# ing916 register map
Vendor: INGChips; Series: ing916xx; File version: 522
CPU: CM4 r0p1, little endian, MPU, FPU, VTOR, 5 interrupt priority bits
Registers are 32-bit, read-write, reset 0x0 unless marked. A register's access mark holds for its fields unless they carry their own. Offsets are from the block's base; [hi:lo] are bit positions; {n}, {i} and the like mark numbered series.

## aon2_ctrl
Base 0x40100000
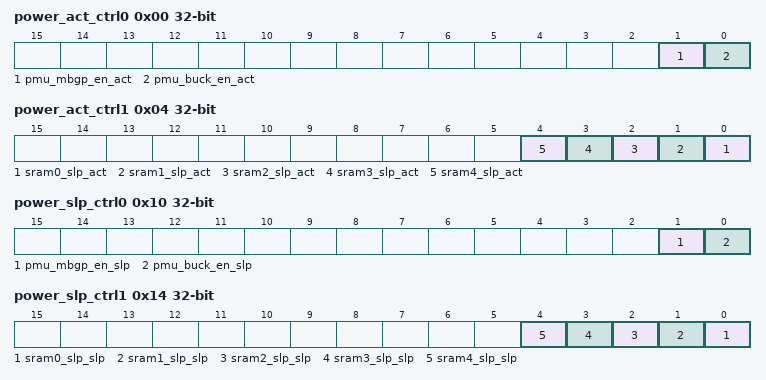
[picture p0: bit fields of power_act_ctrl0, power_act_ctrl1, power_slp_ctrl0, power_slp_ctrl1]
0x00 power_act_ctrl0 — reg description:
  [1] pmu_mbgp_en_act — reg description:
  [0] pmu_buck_en_act — reg description:
0x04 power_act_ctrl1 — reg description:
  [n] sram{n}_slp_act (n=0..4) — reg description:
0x10 power_slp_ctrl0 — reg description:
  [1] pmu_mbgp_en_slp — reg description:
  [0] pmu_buck_en_slp — reg description:
0x14 power_slp_ctrl1 — reg description:
  [n] sram{n}_slp_slp (n=0..4) — reg description:
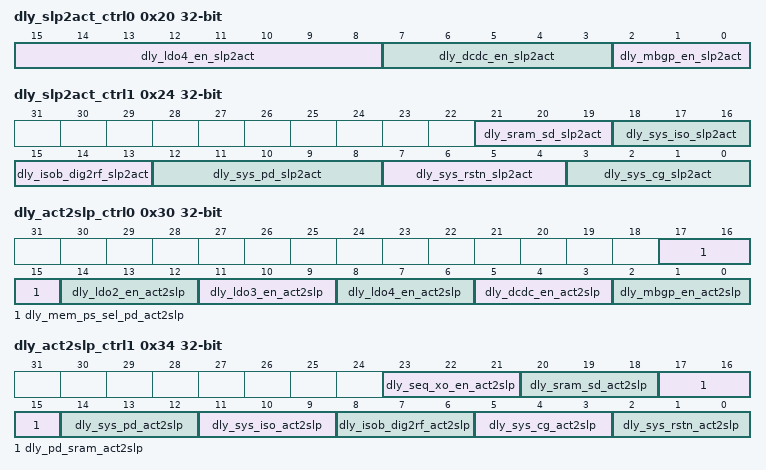
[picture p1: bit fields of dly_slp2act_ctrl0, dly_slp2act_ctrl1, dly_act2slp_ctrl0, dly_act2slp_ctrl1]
0x20 dly_slp2act_ctrl0 — reg description:
  [15:8] dly_ldo4_en_slp2act — reg description:
  [7:3] dly_dcdc_en_slp2act — reg description:
  [2:0] dly_mbgp_en_slp2act — reg description:
0x24 dly_slp2act_ctrl1 — reg description:
  [21:19] dly_sram_sd_slp2act — reg description:
  [18:16] dly_sys_iso_slp2act — reg description:
  [15:13] dly_isob_dig2rf_slp2act — reg description:
  [12:8] dly_sys_pd_slp2act — reg description:
  [7:4] dly_sys_rstn_slp2act — reg description:
  [3:0] dly_sys_cg_slp2act — reg description:
0x30 dly_act2slp_ctrl0 — reg description:
  [17:15] dly_mem_ps_sel_pd_act2slp — reg description:
  [14:12] dly_ldo2_en_act2slp — reg description:
  [11:9] dly_ldo3_en_act2slp — reg description:
  [8:6] dly_ldo4_en_act2slp — reg description:
  [5:3] dly_dcdc_en_act2slp — reg description:
  [2:0] dly_mbgp_en_act2slp — reg description:
0x34 dly_act2slp_ctrl1 — reg description:
  [23:21] dly_seq_xo_en_act2slp — reg description:
  [20:18] dly_sram_sd_act2slp — reg description:
  [17:15] dly_pd_sram_act2slp — reg description:
  [14:12] dly_sys_pd_act2slp — reg description:
  [11:9] dly_sys_iso_act2slp — reg description:
  [8:6] dly_isob_dig2rf_act2slp — reg description:
  [5:3] dly_sys_cg_act2slp — reg description:
  [2:0] dly_sys_rstn_act2slp — reg description:
0x40 pwr_ctrl0 — reg description:
0x60 aon1_reg4 — reg description:
0x64 aon1_reg6 — reg description:
  [3:0] io_ie_aon_35to32
0x68 aon1_reg7 — reg description:
0x6C aon1_reg8 — reg description:
  [3:0] io_pe_aon_35to32
0x70 aon1_reg9 — reg description:
0x74 aon1_reg10 — reg description:
  [3:0] io_ps_aon_35to32
0xB8 aon1_reg_rd11 — reg description:
  [31:0] aon1_rtc_cnt_lsb
0xBC aon1_reg_rd12 — reg description:
  [10:0] aon1_rtc_cnt_msb
0xC0 aon1_reg_rd13 — reg description:
  [31:0] cnt_slp
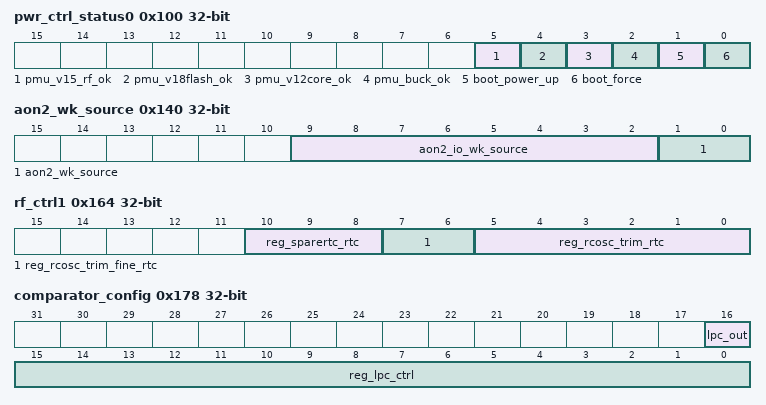
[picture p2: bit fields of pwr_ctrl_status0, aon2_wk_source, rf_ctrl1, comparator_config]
0x100 pwr_ctrl_status0 — reg description:
  [5] pmu_v15_rf_ok — reg description:
  [4] pmu_v18flash_ok — reg description:
  [3] pmu_v12core_ok — reg description:
  [2] pmu_buck_ok — reg description:
  [1] boot_power_up — reg description:
  [0] boot_force — reg description:
0x110 aon_eco_reg0 — reg description:
  [31:0] eco_0
0x114 aon_eco_reg1 — reg description:
  [31:0] eco_1
0x120 sys_wakeup_pol0 — reg description:
  [17:0] reg_wakeup_pol_17to0
0x124 sys_wakeup_pol1 — reg description:
  [8:0] reg_wakeup_pol_msb
0x128 sys_wakeup_en0 — reg description:
  [17:0] reg_wakeup_en_17to0
0x12C sys_wakeup_en1 — reg description:
  [8:0] reg_wakeup_en_msb
0x130 sys_wakeup_mode0 — reg description:
  [31:0] reg_wakeup_mode_0
0x134 sys_wakeup_mode1 — reg description:
  [3:0] reg_wakeup_mode_1_0
0x138 sys_wakeup_mode2 — reg description:
  [17:0] reg_wakeup_mode_2
0x140 aon2_wk_source — reg description:
  [9:2] aon2_io_wk_source — reg description:
  [1:0] aon2_wk_source — reg description:
0x148 aon2_io_aon_i_low — reg description:
0x14C aon2_io_aon_i_high — reg description:
  [5:0] aon2_io_aon_i_high
0x160 rf_ctrl0 — reg description:
0x164 rf_ctrl1 — reg description:
  [10:8] reg_sparertc_rtc — reg description:
  [7:6] reg_rcosc_trim_fine_rtc — reg description:
  [5:0] reg_rcosc_trim_rtc — reg description:
0x174 usb11_phy_config — reg description:
  [8:0] usb_phy_ctrl
0x178 comparator_config — reg description:
  [16] lpc_out — reg description:
  [15:0] reg_lpc_ctrl — reg description:
0x17C rcmfd_config_0 — reg description:
  [16:0] reg_rcmfd_ctrl_0
0x180 rcmfd_config_1 — reg description:
  [23:0] reg_rcmfd_ctrl_1
0x190 dly_fact2lact — reg description:
  [3:0] dly_sys_pd_fact2lact
0x194 dly_lact2fact — reg description:
  [3:0] dly_sys_pd_lact2fact
0x198 dly_cact2fact_0 — reg description:
  [3:0] dly_lle_pd_cact2fact
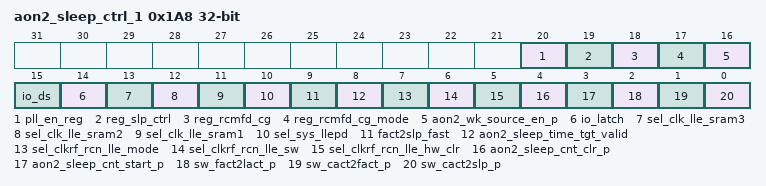
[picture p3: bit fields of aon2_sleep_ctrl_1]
0x1A8 aon2_sleep_ctrl_1 — reg description:
  [20] pll_en_reg — reg description:
  [19] reg_slp_ctrl — reg description:
  [18] reg_rcmfd_cg — reg description:
  [17] reg_rcmfd_cg_mode — reg description:
  [16] aon2_wk_source_en_p — reg description:
  [15] io_ds — reg description:
  [14] io_latch — reg description:
  [13] sel_clk_lle_sram3 — reg description:
  [12] sel_clk_lle_sram2 — reg description:
  [11] sel_clk_lle_sram1 — reg description:
  [10] sel_sys_llepd — reg description:
  [9] fact2slp_fast — reg description:
  [8] aon2_sleep_time_tgt_valid — reg description:
  [7] sel_clkrf_rcn_lle_mode — reg description:
  [6] sel_clkrf_rcn_lle_sw — reg description:
  [5] sel_clkrf_rcn_lle_hw_clr — reg description:
  [4] aon2_sleep_cnt_clr_p — reg description:
  [3] aon2_sleep_cnt_start_p — reg description:
  [2] sw_fact2lact_p — reg description:
  [1] sw_cact2fact_p — reg description:
  [0] sw_cact2slp_p — reg description:
0x1AC aon2_sleep_cnt_rd — reg description:
  [31:0] aon2_sleep_cnt
